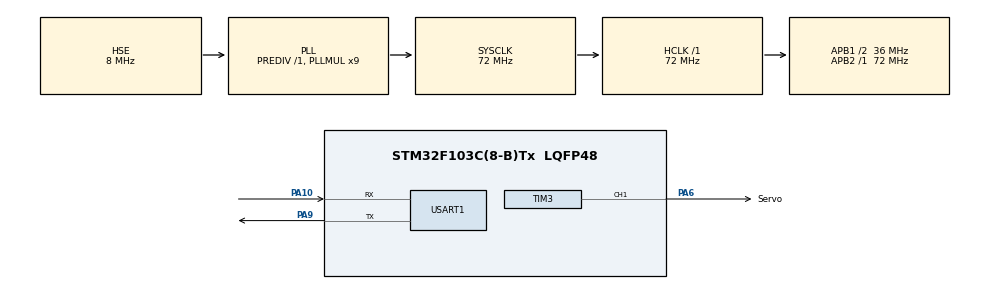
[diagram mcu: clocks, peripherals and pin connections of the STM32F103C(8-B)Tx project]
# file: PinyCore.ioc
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Dma.Request0=TIM3_CH1/TRIG
Dma.TIM3_CH1/TRIG.0.Direction=DMA_PERIPH_TO_MEMORY
Dma.TIM3_CH1/TRIG.0.Instance=DMA1_Channel6
Dma.TIM3_CH1/TRIG.0.MemDataAlignment=DMA_MDATAALIGN_WORD
Dma.TIM3_CH1/TRIG.0.MemInc=DMA_MINC_ENABLE
Dma.TIM3_CH1/TRIG.0.Mode=DMA_CIRCULAR
Dma.TIM3_CH1/TRIG.0.PeriphDataAlignment=DMA_PDATAALIGN_WORD
Dma.TIM3_CH1/TRIG.0.PeriphInc=DMA_PINC_DISABLE
Dma.TIM3_CH1/TRIG.0.Priority=DMA_PRIORITY_LOW
Mcu.Family=STM32F1
Mcu.Name=STM32F103C(8-B)Tx
Mcu.Package=LQFP48
NVIC.DMA1_Channel6_IRQn=true\:0\:0\:false\:false\:true\:false\:true\:true
NVIC.PriorityGroup=NVIC_PRIORITYGROUP_4
NVIC.TIM2_IRQn=true\:15\:0\:false\:false\:true\:false\:true\:true
NVIC.TIM3_IRQn=true\:0\:0\:false\:false\:true\:true\:true\:true
NVIC.TimeBase=TIM2_IRQn
NVIC.TimeBaseIP=TIM2
PA10.Mode=Asynchronous
PA10.Signal=USART1_RX
PA13.Mode=Serial_Wire
PA13.Signal=SYS_JTMS-SWDIO
PA14.Mode=Serial_Wire
PA14.Signal=SYS_JTCK-SWCLK
PA6.GPIO_Label=Servo
PA6.Signal=S_TIM3_CH1
PA9.Mode=Asynchronous
PA9.Signal=USART1_TX
PD0-OSC_IN.Mode=HSE-External-Oscillator
PD0-OSC_IN.Signal=RCC_OSC_IN
PD1-OSC_OUT.Mode=HSE-External-Oscillator
PD1-OSC_OUT.Signal=RCC_OSC_OUT
ProjectManager.HeapSize=0x200
ProjectManager.StackSize=0x400
ProjectManager.TargetToolchain=CMake
RCC.AHBFreq_Value=72000000
RCC.APB1CLKDivider=RCC_HCLK_DIV2
RCC.APB1Freq_Value=36000000
RCC.APB1TimFreq_Value=72000000
RCC.APB2Freq_Value=72000000
RCC.APB2TimFreq_Value=72000000
RCC.HCLKFreq_Value=72000000
RCC.PLLMUL=RCC_PLL_MUL9
RCC.PLLSourceVirtual=RCC_PLLSOURCE_HSE
RCC.SYSCLKFreq_VALUE=72000000
RCC.SYSCLKSource=RCC_SYSCLKSOURCE_PLLCLK
RCC.USBFreq_Value=48000000
RCC.USBPrescaler=RCC_USBCLKSOURCE_PLL_DIV1_5
SH.S_TIM3_CH1.0=TIM3_CH1,PWM Generation1 CH1
TIM3.AutoReloadPreload=TIM_AUTORELOAD_PRELOAD_ENABLE
TIM3.Channel-PWM\ Generation1\ CH1=TIM_CHANNEL_1
TIM3.Period=19999
TIM3.Prescaler=71
USART1.VirtualMode=VM_ASYNC
VP_CRC_VS_CRC.Mode=CRC_Activate
VP_SYS_VS_tim2.Mode=TIM2
board=custom

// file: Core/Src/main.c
/* USER CODE BEGIN Header */
/**
  ******************************************************************************
  * @file           : main.c
  * @brief          : Main program body
  ******************************************************************************
  * @attention
  *
  * Copyright (c) 2026 STMicroelectronics.
  * All rights reserved.
  *
  * This software is licensed under terms that can be found in the LICENSE file
  * in the root directory of this software component.
  * If no LICENSE file comes with this software, it is provided AS-IS.
  *
  ******************************************************************************
  */
/* USER CODE END Header */
#include "main.h"

/* USER CODE BEGIN Includes */
#include "PinyCore.hpp"
/* USER CODE END Includes */

CRC_HandleTypeDef hcrc;

TIM_HandleTypeDef htim3;
DMA_HandleTypeDef hdma_tim3_ch1_trig;

UART_HandleTypeDef huart1;

/* USER CODE BEGIN PV */
// CAN_HandleTypeDef hcan1;
// CAN_HandleTypeDef hcan2;

/* USER CODE END PV */

void SystemClock_Config(void);
static void MX_GPIO_Init(void);
static void MX_DMA_Init(void);
static void MX_CRC_Init(void);
static void MX_TIM3_Init(void);
static void MX_USART1_UART_Init(void);

int main(void)
{

  /* MCU Configuration--------------------------------------------------------*/

  /* Reset of all peripherals, Initializes the Flash interface and the Systick. */
  HAL_Init();

  /* Configure the system clock */
  SystemClock_Config();

  /* Initialize all configured peripherals */
  MX_GPIO_Init();
  MX_DMA_Init();
  MX_CRC_Init();
  MX_TIM3_Init();
  MX_USART1_UART_Init();
  /* USER CODE BEGIN 2 */
  initPinyCore();
  /* USER CODE END 2 */

  /* Infinite loop */
  while (1)
  {

  }
}

void SystemClock_Config(void)
{
  RCC_OscInitTypeDef RCC_OscInitStruct = {0};
  RCC_ClkInitTypeDef RCC_ClkInitStruct = {0};

  /** Initializes the RCC Oscillators according to the specified parameters
  * in the RCC_OscInitTypeDef structure.
  */
  RCC_OscInitStruct.OscillatorType = RCC_OSCILLATORTYPE_HSE;
  RCC_OscInitStruct.HSEState = RCC_HSE_ON;
  RCC_OscInitStruct.HSEPredivValue = RCC_HSE_PREDIV_DIV1;
  RCC_OscInitStruct.HSIState = RCC_HSI_ON;
  RCC_OscInitStruct.PLL.PLLState = RCC_PLL_ON;
  RCC_OscInitStruct.PLL.PLLSource = RCC_PLLSOURCE_HSE;
  RCC_OscInitStruct.PLL.PLLMUL = RCC_PLL_MUL9;
  if (HAL_RCC_OscConfig(&RCC_OscInitStruct) != HAL_OK)
  {
    Error_Handler();
  }

  /** Initializes the CPU, AHB and APB buses clocks
  */
  RCC_ClkInitStruct.ClockType = RCC_CLOCKTYPE_HCLK|RCC_CLOCKTYPE_SYSCLK
                              |RCC_CLOCKTYPE_PCLK1|RCC_CLOCKTYPE_PCLK2;
  RCC_ClkInitStruct.SYSCLKSource = RCC_SYSCLKSOURCE_PLLCLK;
  RCC_ClkInitStruct.AHBCLKDivider = RCC_SYSCLK_DIV1;
  RCC_ClkInitStruct.APB1CLKDivider = RCC_HCLK_DIV2;
  RCC_ClkInitStruct.APB2CLKDivider = RCC_HCLK_DIV1;

  if (HAL_RCC_ClockConfig(&RCC_ClkInitStruct, FLASH_LATENCY_2) != HAL_OK)
  {
    Error_Handler();
  }
}

static void MX_CRC_Init(void)
{

  hcrc.Instance = CRC;
  if (HAL_CRC_Init(&hcrc) != HAL_OK)
  {
    Error_Handler();
  }

}

static void MX_TIM3_Init(void)
{

  TIM_MasterConfigTypeDef sMasterConfig = {0};
  TIM_OC_InitTypeDef sConfigOC = {0};

  htim3.Instance = TIM3;
  htim3.Init.Prescaler = 71;
  htim3.Init.CounterMode = TIM_COUNTERMODE_UP;
  htim3.Init.Period = 19999;
  htim3.Init.ClockDivision = TIM_CLOCKDIVISION_DIV1;
  htim3.Init.AutoReloadPreload = TIM_AUTORELOAD_PRELOAD_ENABLE;
  if (HAL_TIM_PWM_Init(&htim3) != HAL_OK)
  {
    Error_Handler();
  }
  sMasterConfig.MasterOutputTrigger = TIM_TRGO_RESET;
  sMasterConfig.MasterSlaveMode = TIM_MASTERSLAVEMODE_DISABLE;
  if (HAL_TIMEx_MasterConfigSynchronization(&htim3, &sMasterConfig) != HAL_OK)
  {
    Error_Handler();
  }
  sConfigOC.OCMode = TIM_OCMODE_PWM1;
  sConfigOC.Pulse = 0;
  sConfigOC.OCPolarity = TIM_OCPOLARITY_HIGH;
  sConfigOC.OCFastMode = TIM_OCFAST_DISABLE;
  if (HAL_TIM_PWM_ConfigChannel(&htim3, &sConfigOC, TIM_CHANNEL_1) != HAL_OK)
  {
    Error_Handler();
  }
  HAL_TIM_MspPostInit(&htim3);

}

static void MX_USART1_UART_Init(void)
{

  huart1.Instance = USART1;
  huart1.Init.BaudRate = 115200;
  huart1.Init.WordLength = UART_WORDLENGTH_8B;
  huart1.Init.StopBits = UART_STOPBITS_1;
  huart1.Init.Parity = UART_PARITY_NONE;
  huart1.Init.Mode = UART_MODE_TX_RX;
  huart1.Init.HwFlowCtl = UART_HWCONTROL_NONE;
  huart1.Init.OverSampling = UART_OVERSAMPLING_16;
  if (HAL_UART_Init(&huart1) != HAL_OK)
  {
    Error_Handler();
  }

}

static void MX_DMA_Init(void)
{

  /* DMA controller clock enable */
  __HAL_RCC_DMA1_CLK_ENABLE();

  /* DMA interrupt init */
  /* DMA1_Channel6_IRQn interrupt configuration */
  HAL_NVIC_SetPriority(DMA1_Channel6_IRQn, 0, 0);
  HAL_NVIC_EnableIRQ(DMA1_Channel6_IRQn);

}

static void MX_GPIO_Init(void)
{

  /* GPIO Ports Clock Enable */
  __HAL_RCC_GPIOD_CLK_ENABLE();
  __HAL_RCC_GPIOA_CLK_ENABLE();

}

void HAL_TIM_PeriodElapsedCallback(TIM_HandleTypeDef *htim)
{
  if (htim->Instance == TIM2)
  {
    HAL_IncTick();
  }
}

void Error_Handler(void)
{
  __disable_irq();
  while (1)
  {
  }
}
